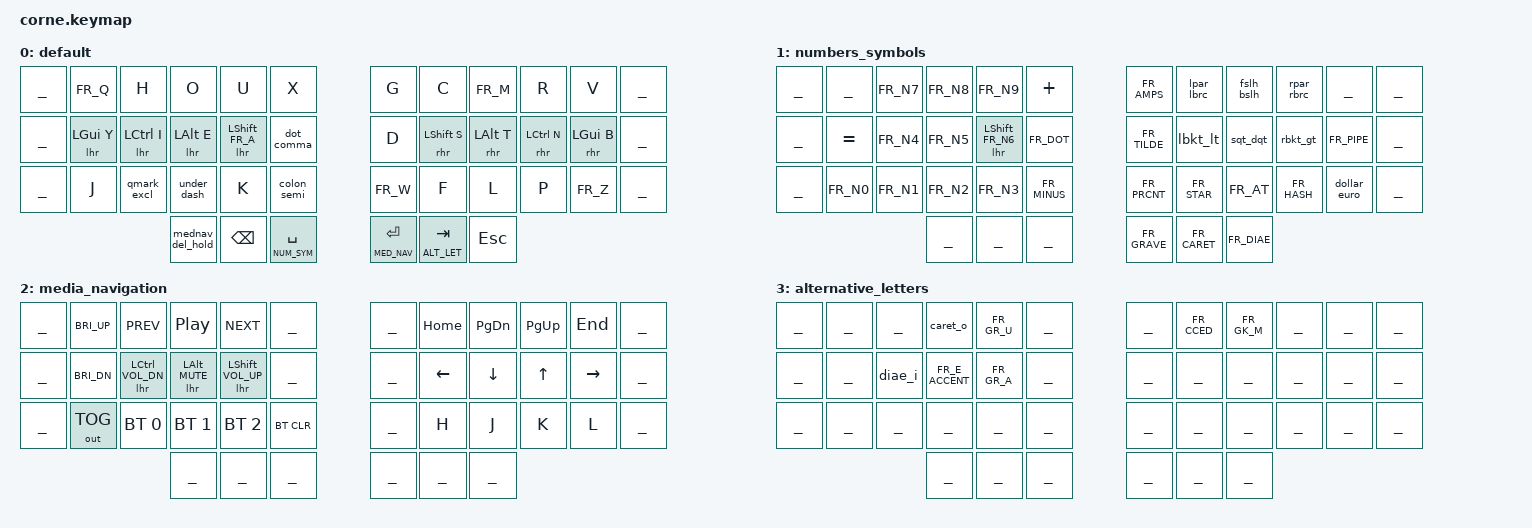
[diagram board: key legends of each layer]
/*
 * Copyright (c) 2020 The ZMK Contributors
 *
 * SPDX-License-Identifier: MIT
 */

#include <behaviors.dtsi>
#include <dt-bindings/zmk/keys.h>
#include <dt-bindings/zmk/bt.h>
#include <dt-bindings/zmk/outputs.h>

#include "keys_fr.h"
#include "helpers.h"
#include "../zmk-nodefree-config/helper.h"

&nice_view_spi {
    cs-gpios = <&pro_micro 9 GPIO_ACTIVE_HIGH>;
};

#define DEFAULT 0
#define NUM_SYM 1
#define MED_NAV 2
#define ALT_LET 3

// ######################################### DEFAULT ######################################### //
ZMK_LAYER(default,
// ╭─────────────────┬─────────────────┬─────────────────┬─────────────────┬─────────────────╮   ╭─────────────────┬─────────────────┬─────────────────┬─────────────────┬─────────────────╮
___     &kp FR_Q            &kp H             &kp O            &kp U              &kp X                 &kp G             &kp C           &kp FR_M            &kp R             &kp V       ___
// ├─────────────────┼─────────────────┼─────────────────┼─────────────────┼──────.───,──────┤   ├─────────────────┼─────────────────┼─────────────────┼─────────────────┼─────────────────┤
___    &lhr LGUI Y      &lhr LCTRL I       &lhr LALT E     &lhr LSHFT FR_A      &dot_comma              &kp D         &rhr LSHFT S       &rhr LALT T      &rhr LCTRL N       &rhr LGUI B    ___
// ├─────────────────┼──────?───!──────┼──────_───-──────┼─────────────────┼──────:───;──────┤   ├─────────────────┼─────────────────┼─────────────────┼─────────────────┼─────────────────┤
___       &kp J          &qmark_excl       &under_dash          &kp K          &colon_semi            &kp FR_W            &kp F             &kp L             &kp P           &kp FR_Z      ___
// ╰─────────────────┴─────────────────┼─────────────────┼─────────────────┼─────────────────┤   ├─────────────────┼─────────────────┼─────────────────┼─────────────────┴─────────────────╯
                                         &mednav_del_hold     &kp BSPC      &lt NUM_SYM SPACE     &lt MED_NAV ENTER  &lt ALT_LET TAB       &kp ESC
//                                     ╰─────────────────┴─────────────────┴─────────────────╯   ╰─────────────────┴─────────────────┴─────────────────╯
)

DEF_LSHFT_KP_MORPH(dot_comma, FR_DOT, FR_COMMA)

DEF_LSHFT_KP_MORPH(colon_semi, FR_COLON, FR_SEMI)
DEF_LSHFT_KP_MORPH(qmark_excl, FR_QMARK, FR_EXCL)
DEF_LSHFT_KP_MORPH(under_dash, FR_UNDER, FR_MINUS)

DEF_LT_DISABLED_ON_SFT(mednav_del_hold, MED_NAV, DEL)
// ########################################################################################### //


// ##################################### NUMBERS_SYMBOLS ##################################### //

ZMK_LAYER(numbers_symbols,
// ╭─────────────────┬─────────────────┬─────────────────┬─────────────────┬─────────────────╮   ╭────────&────────┬──────(───{──────┬──────/───\──────┬──────)───}──────┬─────────────────╮
___        ___           &kp FR_N7         &kp FR_N8          &kp FR_N9         &kp PLUS             &kp FR_AMPS        &lpar_lbrc       &fslh_bslh        &rpar_rbrc            ___        ___
// ├─────────────────┼─────────────────┼─────────────────┼─────────────────┼─────────────────┤   ├────────~────────┼──────[───<──────┼──────'───"──────┼──────]───>──────┼────────|────────┤
___     &kp EQUAL        &kp FR_N4         &kp FR_N5       &lhr LSHFT FR_N6    &kp FR_DOT            &kp FR_TILDE       &lbkt_lt          &sqt_dqt          &rbkt_gt         &kp FR_PIPE    ___
// ├─────────────────┼─────────────────┼─────────────────┼─────────────────┼─────────────────┤   ├────────%────────┼────────*────────┼────────@────────┼────────#────────┼──────$───€──────┤
___     &kp FR_N0        &kp FR_N1         &kp FR_N2          &kp FR_N3       &kp FR_MINUS           &kp FR_PRCNT      &kp FR_STAR        &kp FR_AT        &kp FR_HASH       &dollar_euro   ___
// ╰─────────────────┴─────────────────┼─────────────────┼─────────────────┼─────────────────┤   ├────────`────────┼────────^────────┼────────¨────────┼─────────────────┴─────────────────╯
                                               ___               ___               ___               &kp FR_GRAVE     &kp FR_CARET       &kp FR_DIAE
//                                     ╰─────────────────┴─────────────────┴─────────────────╯   ╰─────────────────┴─────────────────┴─────────────────╯
)

DEF_LSHFT_KP_MORPH(lpar_lbrc, FR_LPAR, FR_LBRC)
DEF_LSHFT_KP_MORPH(fslh_bslh, FR_FSLH, FR_BSLH)
DEF_LSHFT_KP_MORPH(rpar_rbrc, FR_RPAR, FR_RBRC)

DEF_LSHFT_KP_MORPH(lbkt_lt, FR_LBKT, FR_LT)
DEF_LSHFT_KP_MORPH(sqt_dqt, FR_SQT, FR_DQT)
DEF_LSHFT_KP_MORPH(rbkt_gt, FR_RBKT, FR_GT)

DEF_LSHFT_KP_MORPH(dollar_euro, FR_DLLR, FR_EURO)
// ########################################################################################### //


// #################################### MEDIA_NAVIGATION ##################################### //
ZMK_LAYER(media_navigation,
// ╭─────────────────┬─────────────────┬─────────────────┬─────────────────┬─────────────────╮   ╭─────────────────┬─────────────────┬─────────────────┬─────────────────┬─────────────────╮
___   &kp C_BRI_UP       &kp C_PREV         &kp C_PP         &kp C_NEXT            ___                   ___            &kp HOME          &kp PG_DN         &kp PG_UP          &kp END      ___
// ├─────────────────┼─────────────────┼─────────────────┼─────────────────┼─────────────────┤   ├─────────────────┼─────────────────┼─────────────────┼─────────────────┼─────────────────┤
___   &kp C_BRI_DN  &lhr LCTRL C_VOL_DN &lhr LALT C_MUTE &lhr LSHFT C_VOL_UP       ___                   ___            &kp LEFT          &kp DOWN           &kp UP           &kp RIGHT     ___
// ├─────────────────┼─────────────────┼─────────────────┼─────────────────┼─────────────────┤   ├─────────────────┼─────────────────┼─────────────────┼─────────────────┼─────────────────┤
___   &out OUT_TOG      &bt BT_SEL 0      &bt BT_SEL 1      &bt BT_SEL 2       &bt BT_CLR                ___             &kp H              &kp J            &kp K              &kp L       ___
// ╰─────────────────┴─────────────────┼─────────────────┼─────────────────┼─────────────────┤   ├─────────────────┼─────────────────┼─────────────────┼─────────────────┴─────────────────╯
                                               ___               ___               ___                   ___               ___               ___
//                                     ╰─────────────────┴─────────────────┴─────────────────╯   ╰─────────────────┴─────────────────┴─────────────────╯
)
// ########################################################################################### //


// ################################### ALTERNATIVE_LETTERS ################################### //
ZMK_LAYER(alternative_letters,
// ╭─────────────────┬─────────────────┬────────ô────────┬────────ù────────┬─────────────────╮   ╭─────────────────┬────────ç────────┬────────µ────────┬─────────────────┬─────────────────╮
___        ___               ___             &caret_o        &kp FR_GR_U           ___                   ___           &kp FR_CCED       &kp FR_GK_M           ___               ___        ___
// ├─────────────────┼────────ï────────┼────────é────────┼────────à────────┼─────────────────┤   ├─────────────────┼─────────────────┼─────────────────┼─────────────────┼─────────────────┤
___        ___             &diae_i       &kp FR_E_ACCENT     &kp FR_GR_A           ___                   ___               ___               ___               ___               ___        ___
// ├─────────────────┼─────────────────┼─────────────────┼─────────────────┼─────────────────┤   ├─────────────────┼─────────────────┼─────────────────┼─────────────────┼─────────────────┤
___        ___               ___               ___               ___               ___                   ___               ___               ___               ___               ___        ___
// ╰─────────────────┴─────────────────┼─────────────────┼─────────────────┼─────────────────┤   ├─────────────────┼─────────────────┼─────────────────┼─────────────────┴─────────────────╯
                                               ___               ___               ___                   ___               ___               ___
//                                     ╰─────────────────┴─────────────────┴─────────────────╯   ╰─────────────────┴─────────────────┴─────────────────╯
)

/ {
    macros {
       ZMK_MACRO(caret_o,
          wait-ms = <30>;
          tap-ms = <40>;
          bindings = <&kp FR_CARET &kp O>;
       )
       ZMK_MACRO(diae_i,
          wait-ms = <30>;
          tap-ms = <40>;
          bindings = <&kp FR_DIAE &kp I>;
       )
    };
};
// ########################################################################################### //
